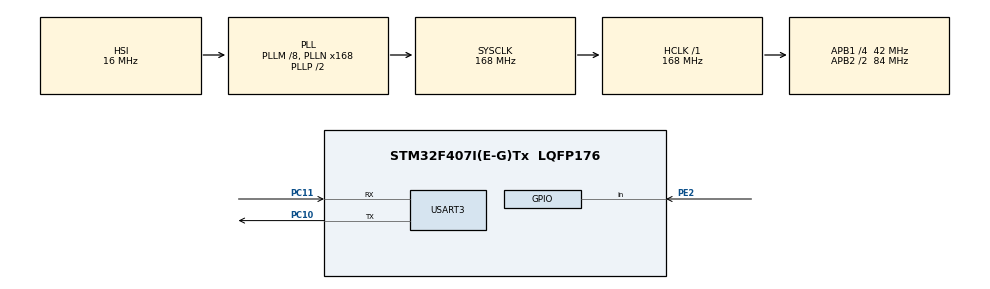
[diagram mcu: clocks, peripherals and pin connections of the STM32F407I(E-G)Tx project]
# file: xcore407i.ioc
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Mcu.Family=STM32F4
Mcu.Name=STM32F407I(E-G)Tx
Mcu.Package=LQFP176
NVIC.PriorityGroup=NVIC_PRIORITYGROUP_4
NVIC.USART3_IRQn=true\:0\:0\:false\:false\:true\:true\:true
PA13.Mode=Serial_Wire
PA13.Signal=SYS_JTMS-SWDIO
PA14.Mode=Serial_Wire
PA14.Signal=SYS_JTCK-SWCLK
PC10.Mode=Asynchronous
PC10.Signal=USART3_TX
PC11.Mode=Asynchronous
PC11.Signal=USART3_RX
PE2.GPIO_PuPd=GPIO_PULLUP
PE2.Signal=GPIO_Input
PH0-OSC_IN.Mode=HSE-External-Oscillator
PH0-OSC_IN.Signal=RCC_OSC_IN
PH1-OSC_OUT.Mode=HSE-External-Oscillator
PH1-OSC_OUT.Signal=RCC_OSC_OUT
ProjectManager.HeapSize=0x200
ProjectManager.StackSize=0x400
ProjectManager.TargetToolchain=SW4STM32
RCC.48MHZClocksFreq_Value=84000000
RCC.AHBFreq_Value=168000000
RCC.APB1CLKDivider=RCC_HCLK_DIV4
RCC.APB1Freq_Value=42000000
RCC.APB1TimFreq_Value=84000000
RCC.APB2CLKDivider=RCC_HCLK_DIV2
RCC.APB2Freq_Value=84000000
RCC.APB2TimFreq_Value=168000000
RCC.CortexFreq_Value=168000000
RCC.HCLKFreq_Value=168000000
RCC.HSE_VALUE=25000000
RCC.HSI_VALUE=16000000
RCC.LSE_VALUE=32768
RCC.PLLM=8
RCC.PLLN=168
RCC.SYSCLKFreq_VALUE=168000000
RCC.SYSCLKSource=RCC_SYSCLKSOURCE_PLLCLK
RCC.VCOOutputFreq_Value=336000000
USART3.VirtualMode=VM_ASYNC
board=custom

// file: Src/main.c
/* USER CODE BEGIN Header */
/**
  ******************************************************************************
  * @file           : main.c
  * @brief          : Main program body
  ******************************************************************************
  * @attention
  *
  * <h2><center>&copy; Copyright (c) 2019 STMicroelectronics.
  * All rights reserved.</center></h2>
  *
  * This software component is licensed by ST under BSD 3-Clause license,
  * the "License"; You may not use this file except in compliance with the
  * License. You may obtain a copy of the License at:
  *                        opensource.org/licenses/BSD-3-Clause
  *
  ******************************************************************************
  */
/* USER CODE END Header */

#include "main.h"

/* USER CODE BEGIN Includes */
#include "config.h"
const uint16_t GPIOS_COUNT = (sizeof(_a_GPIOS)/sizeof(t_GPIO));
t_GPIO *a_GPIOS = _a_GPIOS;

#include "defines.h"
#include "serial.h"
#include "gpios.h"
#include "Model/Button.h"

//#include "Model/Button.h"

/* USER CODE END Includes */

UART_HandleTypeDef huart3;

/* USER CODE BEGIN PV */
#define MAXCLISTRING 200
uint8_t rxBuffer; // where we store that one character that just came in
uint8_t rxString[MAXCLISTRING], rxLastString[MAXCLISTRING]; // where we build our string from characters coming in
int rxindex = 0; // index for going though rxString

t_Button *PR_buttons;
uint16_t PR_Buttons_count = 0;

/* USER CODE END PV */

void SystemClock_Config(void);
static void MX_GPIO_Init(void);
static void MX_USART3_UART_Init(void);

int main(void)
{
  /* USER CODE BEGIN 1 */
//	Model::Button button(GPIOA, GPIO_PIN_7);

  /* USER CODE END 1 */

  /* MCU Configuration--------------------------------------------------------*/

  /* Reset of all peripherals, Initializes the Flash interface and the Systick. */
  HAL_Init();

  /* Configure the system clock */
  SystemClock_Config();

  /* Initialize all configured peripherals */
  MX_GPIO_Init();
  MX_USART3_UART_Init();
  /* USER CODE BEGIN 2 */
  PR_GPIOs_Init();
  PR_Buttons_Init(&PR_buttons, &PR_Buttons_count);

  print("\n\r# > ");
  __HAL_UART_FLUSH_DRREGISTER(&huart3);
  HAL_UART_Receive_IT(&huart3, &rxBuffer, 1);
  /* USER CODE END 2 */

  /* Infinite loop */
  /* USER CODE BEGIN WHILE */
  while (1)
  {
	  if(huart3.RxXferCount == 0)
	  {
		  // HAL_GPIO_TogglePin(GPIOH, GPIO_PIN_2);
		  HAL_UART_Receive_IT(&huart3, &rxBuffer, 1);
	  }

	  PR_Buttons_loop();

//	  HAL_GPIO_WritePin(GPIOH, GPIO_PIN_2, HAL_GPIO_ReadPin(GPIOE, GPIO_PIN_2));
	  HAL_Delay(10);
    /* USER CODE END WHILE */

  }
}

void SystemClock_Config(void)
{
  RCC_OscInitTypeDef RCC_OscInitStruct = {0};
  RCC_ClkInitTypeDef RCC_ClkInitStruct = {0};

  /** Configure the main internal regulator output voltage
  */
  __HAL_RCC_PWR_CLK_ENABLE();
  __HAL_PWR_VOLTAGESCALING_CONFIG(PWR_REGULATOR_VOLTAGE_SCALE1);
  /** Initializes the CPU, AHB and APB busses clocks
  */
  RCC_OscInitStruct.OscillatorType = RCC_OSCILLATORTYPE_HSI;
  RCC_OscInitStruct.HSIState = RCC_HSI_ON;
  RCC_OscInitStruct.HSICalibrationValue = RCC_HSICALIBRATION_DEFAULT;
  RCC_OscInitStruct.PLL.PLLState = RCC_PLL_ON;
  RCC_OscInitStruct.PLL.PLLSource = RCC_PLLSOURCE_HSI;
  RCC_OscInitStruct.PLL.PLLM = 8;
  RCC_OscInitStruct.PLL.PLLN = 168;
  RCC_OscInitStruct.PLL.PLLP = RCC_PLLP_DIV2;
  RCC_OscInitStruct.PLL.PLLQ = 4;
  if (HAL_RCC_OscConfig(&RCC_OscInitStruct) != HAL_OK)
  {
    Error_Handler();
  }
  /** Initializes the CPU, AHB and APB busses clocks
  */
  RCC_ClkInitStruct.ClockType = RCC_CLOCKTYPE_HCLK|RCC_CLOCKTYPE_SYSCLK
                              |RCC_CLOCKTYPE_PCLK1|RCC_CLOCKTYPE_PCLK2;
  RCC_ClkInitStruct.SYSCLKSource = RCC_SYSCLKSOURCE_PLLCLK;
  RCC_ClkInitStruct.AHBCLKDivider = RCC_SYSCLK_DIV1;
  RCC_ClkInitStruct.APB1CLKDivider = RCC_HCLK_DIV4;
  RCC_ClkInitStruct.APB2CLKDivider = RCC_HCLK_DIV2;

  if (HAL_RCC_ClockConfig(&RCC_ClkInitStruct, FLASH_LATENCY_5) != HAL_OK)
  {
    Error_Handler();
  }
}

static void MX_USART3_UART_Init(void)
{

  huart3.Instance = USART3;
  huart3.Init.BaudRate = 115200;
  huart3.Init.WordLength = UART_WORDLENGTH_8B;
  huart3.Init.StopBits = UART_STOPBITS_1;
  huart3.Init.Parity = UART_PARITY_NONE;
  huart3.Init.Mode = UART_MODE_TX_RX;
  huart3.Init.HwFlowCtl = UART_HWCONTROL_NONE;
  huart3.Init.OverSampling = UART_OVERSAMPLING_16;
  if (HAL_UART_Init(&huart3) != HAL_OK)
  {
    Error_Handler();
  }

}

static void MX_GPIO_Init(void)
{
  GPIO_InitTypeDef GPIO_InitStruct = {0};

  /* GPIO Ports Clock Enable */
  __HAL_RCC_GPIOE_CLK_ENABLE();
  __HAL_RCC_GPIOH_CLK_ENABLE();
  __HAL_RCC_GPIOA_CLK_ENABLE();
  __HAL_RCC_GPIOC_CLK_ENABLE();

  /*Configure GPIO pin : PE2 */
  GPIO_InitStruct.Pin = GPIO_PIN_2;
  GPIO_InitStruct.Mode = GPIO_MODE_INPUT;
  GPIO_InitStruct.Pull = GPIO_PULLUP;
  //HAL_GPIO_Init(GPIOE, &GPIO_InitStruct);

}

/* USER CODE BEGIN 4 */
void HAL_UART_RxCpltCallback(UART_HandleTypeDef *huart)
{
	__HAL_UART_FLUSH_DRREGISTER(&huart3); // Clear the buffer to prevent overrun

	int i = 0;

	if (rxBuffer == '\003'){ // Ctrl+C
		SR_setSerialStatus(UART_STATUS_INPUT);
		rxindex = 0;
		for (i = 0; i < MAXCLISTRING; i++) rxString[i] = 0; // Clear the string buffer
		print("\n\r# > ");
	} else if (SR_getSerialStatus() == UART_STATUS_LOGS) {
		// do nothing
	} else if (rxBuffer == '\e') { // Waiting an arrow
		SR_setSerialStatus(UART_STATUS_ARROW);
	} else if (SR_getSerialStatus() == UART_STATUS_ARROW) {
		if (rxBuffer != '[') {
			switch (rxBuffer) {
				case 'A':
					for (; rxindex > 0; rxindex--) {
						print("\b \b");
					}
					// code for arrow up
					memcpy(rxString, rxLastString, MAXCLISTRING);
					rxindex = strlen(rxString);
					print(rxString);
					break;
				case 'B':
					// code for arrow down
					break;
				case 'C':
					// code for arrow right
					break;
				case 'D':
					// code for arrow left
					break;
			}
			SR_setSerialStatus(UART_STATUS_INPUT);
		}
	} else if (rxBuffer == 8 || rxBuffer == 127) { // If Backspace or del
		rxindex--;
		if (rxindex < 0) {
			rxindex = 0;
		} else {
			print("\b \b"); // "\b space \b" clears the terminal character. Remember we just echoced a \b so don't need another one here, just space and \b
		}
		rxString[rxindex] = 0;
	} else if (rxBuffer == '\n' || rxBuffer == '\r') { // If Enter
		print("\n\r");
		memcpy(rxLastString, rxString, MAXCLISTRING);

		SR_execCommand(rxString);

		for (int i = 0; i < MAXCLISTRING; i++) {
			rxString[i] = 0; // Clear the string buffer
		}

		rxString[rxindex] = 0;
		rxindex = 0;

		if (SR_getSerialStatus() != UART_STATUS_LOGS) {
			print("\n\r# > ");
		}

	} else if (isprint(rxBuffer)){
		print(&rxBuffer); // Echo the character that caused this callback so the user can see what they are typing

		rxString[rxindex] = rxBuffer; // Add that character to the string
		rxindex++;
		if (rxindex > MAXCLISTRING) { // User typing too much, we can't have commands that big
			rxindex = 0;
			for (i = 0; i < MAXCLISTRING; i++) rxString[i] = 0; // Clear the string buffer
			print("\n\r# > ");
		}
	}
}

void print(char *str)
{
	HAL_UART_Transmit(&huart3, (uint8_t*)str, strlen(str), 0xFFFF);
}

void info(char *str)
{
	if (SR_getSerialStatus() == UART_STATUS_LOGS) {
		print(str);
	}
}

char *getFwVersion()
{
	return FW_VERSION;
}
/* USER CODE END 4 */

void Error_Handler(void)
{
}

/************************ (C) COPYRIGHT STMicroelectronics *****END OF FILE****/
